AUTOSAR XML (schema 00046)
package /ComponentTypes
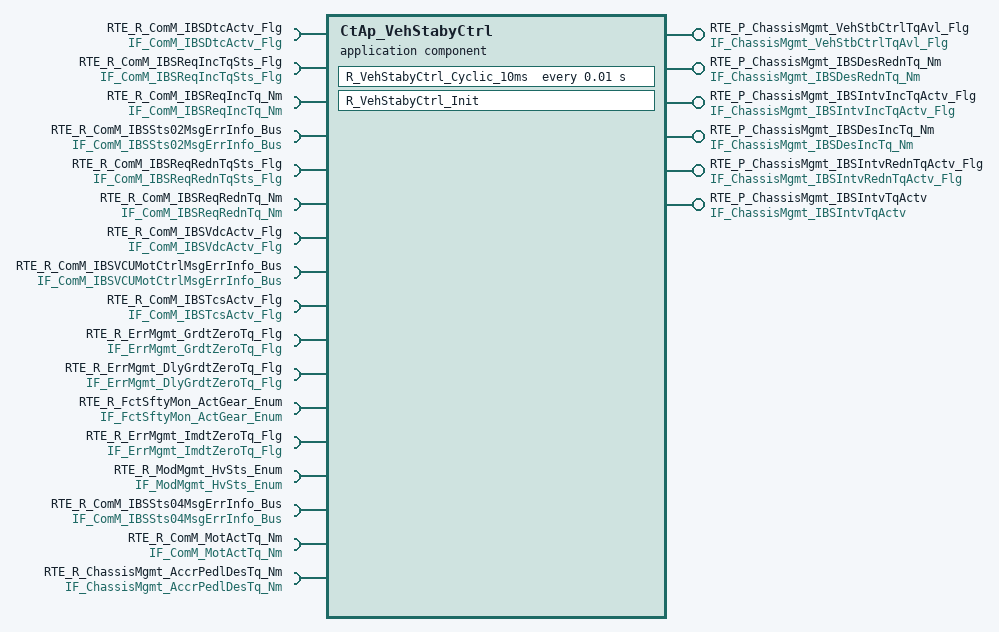
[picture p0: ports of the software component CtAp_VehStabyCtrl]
  application sw component type CtAp_VehStabyCtrl
    5 x provide port:
      RTE_P_ChassisMgmt_VehStbCtrlTqAvl_Flg: nonqueued-sender-com-spec{data-element=tec_ChassisMgmt_VehStbCtrlTqAvl_Flg, init-value=0}, provided-interface=IF_ChassisMgmt_VehStbCtrlTqAvl_Flg
      RTE_P_ChassisMgmt_IBSDesRednTq_Nm: nonqueued-sender-com-spec{data-element=tec_ChassisMgmt_IBSDesRednTq_Nm, init-value=0}, provided-interface=IF_ChassisMgmt_IBSDesRednTq_Nm
      RTE_P_ChassisMgmt_IBSIntvIncTqActv_Flg: nonqueued-sender-com-spec{data-element=tec_ChassisMgmt_IBSIntvIncTqActv_Flg, init-value=0}, provided-interface=IF_ChassisMgmt_IBSIntvIncTqActv_Flg
      RTE_P_ChassisMgmt_IBSDesIncTq_Nm: nonqueued-sender-com-spec{data-element=tec_ChassisMgmt_IBSDesIncTq_Nm, init-value=0}, provided-interface=IF_ChassisMgmt_IBSDesIncTq_Nm
      RTE_P_ChassisMgmt_IBSIntvRednTqActv_Flg: nonqueued-sender-com-spec{data-element=tec_ChassisMgmt_IBSIntvRednTqActv_Flg, init-value=0}, provided-interface=IF_ChassisMgmt_IBSIntvRednTqActv_Flg
    15 x require port:
      RTE_R_ComM_IBSDtcActv_Flg: nonqueued-receiver-com-spec{data-element=tec_ComM_IBSDtcActv_Flg, filter=data-filter-type=ALWAYS, init-value=0}, required-interface=IF_ComM_IBSDtcActv_Flg
      RTE_R_ComM_IBSReqIncTqSts_Flg: nonqueued-receiver-com-spec{data-element=tec_ComM_IBSReqIncTqSts_Flg, filter=data-filter-type=ALWAYS, init-value=0}, required-interface=IF_ComM_IBSReqIncTqSts_Flg
      RTE_R_ComM_IBSReqIncTq_Nm: nonqueued-receiver-com-spec{data-element=tec_ComM_IBSReqIncTq_Nm, filter=data-filter-type=ALWAYS, init-value=0}, required-interface=IF_ComM_IBSReqIncTq_Nm
      RTE_R_ComM_IBSSts02MsgErrInfo_Bus: required-interface=IF_ComM_IBSSts02MsgErrInfo_Bus
        required-com-specs:
          data-element=tec_ComM_IBSSts02CRCInfo_Bus, filter=data-filter-type=ALWAYS, init-value=fields=[ComM_MonStatIBSSts02CRCErrorInfo:0, ComM_MonResIBSSts02CRCErrorInfo:0, ComM_ErrStatIBSSts02CRCErrorInfo:0, ComM_ErrResIBSSts02CRCErrorInfo:0]
          data-element=tec_ComM_IBSSts02CRCDTCInfo_Bus, filter=data-filter-type=ALWAYS, init-value=fields=[ComM_MonStatIBSSts02CRCDTCErrorInfo:0, ComM_MonResIBSSts02CRCDTCErrorInfo:0, ComM_ErrStatIBSSts02CRCDTCErrorInfo:0, ComM_ErrResIBSSts02CRCDTCErrorInfo:0]
          data-element=tec_ComM_IBSSts02TimeoutDTCInfo_Bus, filter=data-filter-type=ALWAYS, init-value=fields=[ComM_MonStatIBSSts02TimeoutDTCErrorInfo:0, ComM_MonResIBSSts02TimeoutDTCErrorInfo:0, ComM_ErrStatIBSSts02TimeoutDTCErrorInfo:0, ComM_ErrResIBSSts02TimeoutDTCErrorInfo:0]
          data-element=tec_ComM_IBSSts02E2ETimeoutInfo_Bus, filter=data-filter-type=ALWAYS, init-value=fields=[ComM_MonStatIBSSts02E2ETimeoutInfo:0, ComM_MonResIBSSts02E2ETimeoutInfo:0, ComM_ErrStatIBSSts02E2ETimeoutInfo:0, ComM_ErrResIBSSts02E2ETimeoutInfo:0]
      RTE_R_ComM_IBSReqRednTqSts_Flg: nonqueued-receiver-com-spec{data-element=tec_ComM_IBSReqRednTqSts_Flg, filter=data-filter-type=ALWAYS, init-value=0}, required-interface=IF_ComM_IBSReqRednTqSts_Flg
      RTE_R_ComM_IBSReqRednTq_Nm: nonqueued-receiver-com-spec{data-element=tec_ComM_IBSReqRednTq_Nm, filter=data-filter-type=ALWAYS, init-value=0}, required-interface=IF_ComM_IBSReqRednTq_Nm
      RTE_R_ComM_IBSVdcActv_Flg: nonqueued-receiver-com-spec{data-element=tec_ComM_IBSVdcActv_Flg, filter=data-filter-type=ALWAYS, init-value=0}, required-interface=IF_ComM_IBSVdcActv_Flg
      RTE_R_ComM_IBSVCUMotCtrlMsgErrInfo_Bus: required-interface=IF_ComM_IBSVCUMotCtrlMsgErrInfo_Bus
        required-com-specs:
          data-element=tec_ComM_IBSVCUMotCtrlCRCDTCInfo_Bus, filter=data-filter-type=ALWAYS, init-value=fields=[ComM_MonStatIBSVCUMotCtrlCRCDTCErrorInfo:0, ComM_MonResIBSVCUMotCtrlCRCDTCErrorInfo:0, ComM_ErrStatIBSVCUMotCtrlCRCDTCErrorInfo:0, ComM_ErrResIBSVCUMotCtrlCRCDTCErrorInfo:0]
          data-element=tec_ComM_IBSVCUMotCtrlTimeoutInfo_Bus, filter=data-filter-type=ALWAYS, init-value=fields=[ComM_MonStatIBSVCUMotCtrlTimeoutInfo:0, ComM_MonResIBSVCUMotCtrlTimeoutInfo:0, ComM_ErrStatIBSVCUMotCtrlTimeoutInfo:0, ComM_ErrResIBSVCUMotCtrlTimeoutInfo:0]
          data-element=tec_ComM_IBSVCUMotCtrlCRCInfo_Bus, filter=data-filter-type=ALWAYS, init-value=fields=[ComM_MonStatIBSVCUMotCtrlCRCErrorInfo:0, ComM_MonResIBSVCUMotCtrlCRCErrorInfo:0, ComM_ErrStatIBSVCUMotCtrlCRCErrorInfo:0, ComM_ErrResIBSVCUMotCtrlCRCErrorInfo:0]
          data-element=tec_ComM_IBSVCUMotCtrlTimeoutDTCInfo_Bus, filter=data-filter-type=ALWAYS, init-value=fields=[ComM_MonStatIBSVCUMotCtrlTimeoutDTCErrorInfo:0, ComM_MonResIBSVCUMotCtrlTimeoutDTCErrorInfo:0, ComM_ErrStatIBSVCUMotCtrlTimeoutDTCErrorInfo:0, ComM_ErrResIBSVCUMotCtrlTimeoutDTCErrorInfo:0]
          data-element=tec_ComM_IBSVCUMotCtrlE2ETimeoutInfo_Bus, filter=data-filter-type=ALWAYS, init-value=fields=[ComM_MonStatIBSVCUMotCtrlE2ETimeoutInfo:0, ComM_MonResIBSVCUMotCtrlE2ETimeoutInfo:0, ComM_ErrStatIBSVCUMotCtrlE2ETimeoutInfo:0, ComM_ErrResIBSVCUMotCtrlE2ETimeoutInfo:0]
      RTE_R_ComM_IBSTcsActv_Flg: nonqueued-receiver-com-spec{data-element=tec_ComM_IBSTcsActv_Flg, filter=data-filter-type=ALWAYS, init-value=0}, required-interface=IF_ComM_IBSTcsActv_Flg
      RTE_R_ErrMgmt_GrdtZeroTq_Flg: nonqueued-receiver-com-spec{data-element=tec_ErrMgmt_GrdtZeroTq_Flg, filter=data-filter-type=ALWAYS, init-value=0}, required-interface=IF_ErrMgmt_GrdtZeroTq_Flg
      RTE_R_ErrMgmt_DlyGrdtZeroTq_Flg: nonqueued-receiver-com-spec{data-element=tec_ErrMgmt_DlyGrdtZeroTq_Flg, filter=data-filter-type=ALWAYS, init-value=0}, required-interface=IF_ErrMgmt_DlyGrdtZeroTq_Flg
      RTE_R_FctSftyMon_ActGear_Enum: nonqueued-receiver-com-spec{data-element=tec_FctSftyMon_ActGear_Enum, filter=data-filter-type=ALWAYS, init-value=0}, required-interface=IF_FctSftyMon_ActGear_Enum
      RTE_R_ErrMgmt_ImdtZeroTq_Flg: nonqueued-receiver-com-spec{data-element=tec_ErrMgmt_ImdtZeroTq_Flg, filter=data-filter-type=ALWAYS, init-value=0}, required-interface=IF_ErrMgmt_ImdtZeroTq_Flg
      RTE_R_ModMgmt_HvSts_Enum: nonqueued-receiver-com-spec{data-element=tec_ModMgmt_HvSts_Enum, filter=data-filter-type=ALWAYS, init-value=0}, required-interface=IF_ModMgmt_HvSts_Enum
      RTE_R_ComM_IBSSts04MsgErrInfo_Bus: required-interface=IF_ComM_IBSSts04MsgErrInfo_Bus
        required-com-specs:
          data-element=tec_ComM_IBSSts04CRCDTCInfo_Bus, filter=data-filter-type=ALWAYS, init-value=fields=[ComM_MonStatIBSSts04CRCDTCErrorInfo:0, ComM_MonResIBSSts04CRCDTCErrorInfo:0, ComM_ErrStatIBSSts04CRCDTCErrorInfo:0, ComM_ErrResIBSSts04CRCDTCErrorInfo:0]
          data-element=tec_ComM_IBSSts04CRCInfo_Bus, filter=data-filter-type=ALWAYS, init-value=fields=[ComM_MonStatIBSSts04CRCErrorInfo:0, ComM_MonResIBSSts04CRCErrorInfo:0, ComM_ErrStatIBSSts04CRCErrorInfo:0, ComM_ErrResIBSSts04CRCErrorInfo:0]
          data-element=tec_ComM_IBSSts04TimeoutDTCInfo_Bus, filter=data-filter-type=ALWAYS, init-value=fields=[ComM_MonStatIBSSts04TimeoutDTCErrorInfo:0, ComM_MonResIBSSts04TimeoutDTCErrorInfo:0, ComM_ErrStatIBSSts04TimeoutDTCErrorInfo:0, ComM_ErrResIBSSts04TimeoutDTCErrorInfo:0]
          data-element=tec_ComM_IBSSts04E2ETimeoutInfo_Bus, filter=data-filter-type=ALWAYS, init-value=fields=[ComM_MonStatIBSSts04E2ETimeoutInfo:0, ComM_MonResIBSSts04E2ETimeoutInfo:0, ComM_ErrStatIBSSts04E2ETimeoutInfo:0, ComM_ErrResIBSSts04E2ETimeoutInfo:0]
    provide port RTE_P_ChassisMgmt_IBSIntvTqActv: nonqueued-sender-com-spec{data-element=tec_ChassisMgmt_IBSIntvTqActv, init-value=0}, provided-interface=IF_ChassisMgmt_IBSIntvTqActv
    require port RTE_R_ComM_MotActTq_Nm: nonqueued-receiver-com-spec{data-element=tec_ComM_MotActTq_Nm, filter=data-filter-type=ALWAYS, init-value=0}, required-interface=IF_ComM_MotActTq_Nm
    require port RTE_R_ChassisMgmt_AccrPedlDesTq_Nm: nonqueued-receiver-com-spec{data-element=tec_ChassisMgmt_AccrPedlDesTq_Nm, filter=data-filter-type=ALWAYS, init-value=0}, required-interface=IF_ChassisMgmt_AccrPedlDesTq_Nm
    behavior CtAp_VehStabyCtrl_InternalBehavior
      timing event TMT_R_VehStabyCtrl_Cyclic_10ms: start-on-event=R_VehStabyCtrl_Cyclic_10ms, period=0.01
      init event CtAp_VehStabyCtrl_InitEvent: start-on-event=R_VehStabyCtrl_Init
      runnable R_VehStabyCtrl_Cyclic_10ms
        data-receive-point-by-arguments:
          20 x access:
            REC_RTE_R_ComM_IBSDtcActv_Flg_tec_ComM_IBSDtcActv_Flg: accessed-variable=RTE_R_ComM_IBSDtcActv_Flg.tec_ComM_IBSDtcActv_Flg
            REC_RTE_R_ComM_IBSReqIncTqSts_Flg_tec_ComM_IBSReqIncTqSts_Flg: accessed-variable=RTE_R_ComM_IBSReqIncTqSts_Flg.tec_ComM_IBSReqIncTqSts_Flg
            REC_RTE_R_ComM_IBSReqIncTq_Nm_tec_ComM_IBSReqIncTq_Nm: accessed-variable=RTE_R_ComM_IBSReqIncTq_Nm.tec_ComM_IBSReqIncTq_Nm
            REC_RTE_R_ComM_IBSReqRednTqSts_Flg_tec_ComM_IBSReqRednTqSts_Flg: accessed-variable=RTE_R_ComM_IBSReqRednTqSts_Flg.tec_ComM_IBSReqRednTqSts_Flg
            REC_RTE_R_ComM_IBSReqRednTq_Nm_tec_ComM_IBSReqRednTq_Nm: accessed-variable=RTE_R_ComM_IBSReqRednTq_Nm.tec_ComM_IBSReqRednTq_Nm
            REC_RTE_R_ComM_IBSSts02MsgErrInfo_Bus_tec_ComM_IBSSts02CRCInfo_Bus: accessed-variable=RTE_R_ComM_IBSSts02MsgErrInfo_Bus.tec_ComM_IBSSts02CRCInfo_Bus
            REC_RTE_R_ComM_IBSSts02MsgErrInfo_Bus_tec_ComM_IBSSts02E2ETimeoutInfo_Bus: accessed-variable=RTE_R_ComM_IBSSts02MsgErrInfo_Bus.tec_ComM_IBSSts02E2ETimeoutInfo_Bus
            REC_RTE_R_ComM_IBSTcsActv_Flg_tec_ComM_IBSTcsActv_Flg: accessed-variable=RTE_R_ComM_IBSTcsActv_Flg.tec_ComM_IBSTcsActv_Flg
            REC_RTE_R_ComM_IBSVCUMotCtrlMsgErrInfo_Bus_tec_ComM_IBSVCUMotCtrlCRCInfo_Bus: accessed-variable=RTE_R_ComM_IBSVCUMotCtrlMsgErrInfo_Bus.tec_ComM_IBSVCUMotCtrlCRCInfo_Bus
            REC_RTE_R_ComM_IBSVCUMotCtrlMsgErrInfo_Bus_tec_ComM_IBSVCUMotCtrlE2ETimeoutInfo_Bus: accessed-variable=RTE_R_ComM_IBSVCUMotCtrlMsgErrInfo_Bus.tec_ComM_IBSVCUMotCtrlE2ETimeoutInfo_Bus
            REC_RTE_R_ComM_IBSVdcActv_Flg_tec_ComM_IBSVdcActv_Flg: accessed-variable=RTE_R_ComM_IBSVdcActv_Flg.tec_ComM_IBSVdcActv_Flg
            REC_RTE_R_ErrMgmt_DlyGrdtZeroTq_Flg_tec_ErrMgmt_DlyGrdtZeroTq_Flg: accessed-variable=RTE_R_ErrMgmt_DlyGrdtZeroTq_Flg.tec_ErrMgmt_DlyGrdtZeroTq_Flg
            REC_RTE_R_ErrMgmt_GrdtZeroTq_Flg_tec_ErrMgmt_GrdtZeroTq_Flg: accessed-variable=RTE_R_ErrMgmt_GrdtZeroTq_Flg.tec_ErrMgmt_GrdtZeroTq_Flg
            REC_RTE_R_ErrMgmt_ImdtZeroTq_Flg_tec_ErrMgmt_ImdtZeroTq_Flg: accessed-variable=RTE_R_ErrMgmt_ImdtZeroTq_Flg.tec_ErrMgmt_ImdtZeroTq_Flg
            REC_RTE_R_FctSftyMon_ActGear_Enum_tec_FctSftyMon_ActGear_Enum: accessed-variable=RTE_R_FctSftyMon_ActGear_Enum.tec_FctSftyMon_ActGear_Enum
            REC_RTE_R_ModMgmt_HvSts_Enum_tec_ModMgmt_HvSts_Enum: accessed-variable=RTE_R_ModMgmt_HvSts_Enum.tec_ModMgmt_HvSts_Enum
            REC_RTE_R_ComM_IBSSts04MsgErrInfo_Bus_tec_ComM_IBSSts04CRCInfo_Bus: accessed-variable=RTE_R_ComM_IBSSts04MsgErrInfo_Bus.tec_ComM_IBSSts04CRCInfo_Bus
            REC_RTE_R_ComM_IBSSts04MsgErrInfo_Bus_tec_ComM_IBSSts04E2ETimeoutInfo_Bus: accessed-variable=RTE_R_ComM_IBSSts04MsgErrInfo_Bus.tec_ComM_IBSSts04E2ETimeoutInfo_Bus
            REC_RTE_R_ComM_MotActTq_Nm_tec_ComM_MotActTq_Nm: accessed-variable=RTE_R_ComM_MotActTq_Nm.tec_ComM_MotActTq_Nm
            REC_RTE_R_ChassisMgmt_AccrPedlDesTq_Nm_tec_ChassisMgmt_AccrPedlDesTq_Nm: accessed-variable=RTE_R_ChassisMgmt_AccrPedlDesTq_Nm.tec_ChassisMgmt_AccrPedlDesTq_Nm
        data-send-points:
          6 x access:
            SEND_RTE_P_ChassisMgmt_IBSIntvIncTqActv_Flg_tec_ChassisMgmt_IBSIntvIncTqActv_Flg: accessed-variable=RTE_P_ChassisMgmt_IBSIntvIncTqActv_Flg.tec_ChassisMgmt_IBSIntvIncTqActv_Flg
            SEND_RTE_P_ChassisMgmt_IBSIntvRednTqActv_Flg_tec_ChassisMgmt_IBSIntvRednTqActv_Flg: accessed-variable=RTE_P_ChassisMgmt_IBSIntvRednTqActv_Flg.tec_ChassisMgmt_IBSIntvRednTqActv_Flg
            SEND_RTE_P_ChassisMgmt_VehStbCtrlTqAvl_Flg_tec_ChassisMgmt_VehStbCtrlTqAvl_Flg: accessed-variable=RTE_P_ChassisMgmt_VehStbCtrlTqAvl_Flg.tec_ChassisMgmt_VehStbCtrlTqAvl_Flg
            SEND_RTE_P_ChassisMgmt_IBSDesIncTq_Nm_tec_ChassisMgmt_IBSDesIncTq_Nm: accessed-variable=RTE_P_ChassisMgmt_IBSDesIncTq_Nm.tec_ChassisMgmt_IBSDesIncTq_Nm
            SEND_RTE_P_ChassisMgmt_IBSDesRednTq_Nm_tec_ChassisMgmt_IBSDesRednTq_Nm: accessed-variable=RTE_P_ChassisMgmt_IBSDesRednTq_Nm.tec_ChassisMgmt_IBSDesRednTq_Nm
            SEND_RTE_P_ChassisMgmt_IBSIntvTqActv_tec_ChassisMgmt_IBSIntvTqActv: accessed-variable=RTE_P_ChassisMgmt_IBSIntvTqActv.tec_ChassisMgmt_IBSIntvTqActv
      runnable R_VehStabyCtrl_Init
  swc implementation CtAp_VehStabyCtrl_Implementation: behavior=CtAp_VehStabyCtrl_InternalBehavior
